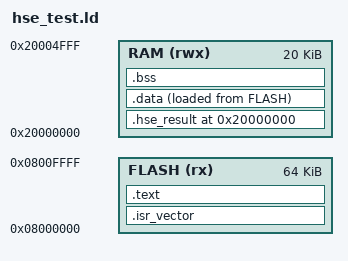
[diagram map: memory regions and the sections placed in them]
ENTRY(Reset_Handler)

_estack = ORIGIN(RAM) + LENGTH(RAM);

MEMORY
{
    FLASH (rx)  : ORIGIN = 0x08000000, LENGTH = 64K
    RAM   (rwx) : ORIGIN = 0x20000000, LENGTH = 20K
}

SECTIONS
{
    .isr_vector :
    {
        . = ALIGN(4);
        KEEP(*(.isr_vector))
        . = ALIGN(4);
    } > FLASH

    .text :
    {
        . = ALIGN(4);
        *(.text*)
        *(.rodata*)
        . = ALIGN(4);
    } > FLASH

    _sidata = LOADADDR(.data);

    .hse_result 0x20000000 (NOLOAD) :
    {
        . = ALIGN(4);
        KEEP(*(.hse_result))
        . = ALIGN(4);
    } > RAM

    .data :
    {
        . = ALIGN(4);
        _sdata = .;
        *(.data*)
        . = ALIGN(4);
        _edata = .;
    } > RAM AT > FLASH

    .bss (NOLOAD) :
    {
        . = ALIGN(4);
        _sbss = .;
        *(.bss*)
        *(COMMON)
        . = ALIGN(4);
        _ebss = .;
    } > RAM

    /DISCARD/ :
    {
        *(.comment)
        *(.note*)
        *(.eh_frame*)
    }
}
